# SN32F420 register map
Vendor: SONiX Technology Co., Ltd.; Series: SN32F420; File version: 1.00
CPU: CM0 r0p0, little endian, no MPU, no FPU, 2 interrupt priority bits
Registers are 32-bit, read-write, reset 0x0 unless marked. A register's access mark holds for its fields unless they carry their own. Offsets are from the block's base; [hi:lo] are bit positions.

## SN_DAC — DAC
Base 0x40064000
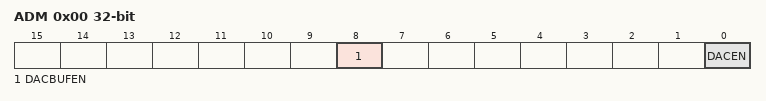
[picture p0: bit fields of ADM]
0x00 ADM — Offset:0x00 DAC Management register
  [8] DACBUFEN — DAC0 Output buffer enable bit
    0=Disable DAO; 1=Enable DAO
  [0] DACEN — DAC0 enable bit
    0=Disable DAC; 1=Enable DAC
0x04 VIREF — Offset:0x04 DAC Internal Reference Voltage Source register
  [0] VIREF — DAC internal reference voltage (VIREF) source
    0=1.2V (DAC internal reference voltage (VIREF) source is 1.2V); 1=4.8V (DAC internal reference voltage (VIREF) source is 4.8V)
0x10 DATACTRL — Offset:0x10 DAC Data Control register
  [7:0] DATA — 8-bit DAC setup data bits.

## SN_ACC — Atan, Div and Sqrt Function
Base 0x40076000
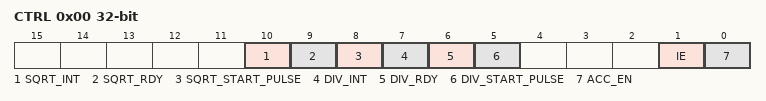
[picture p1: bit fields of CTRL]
0x00 CTRL — Offset:0x00 ACC Hardware Calculation Accelerator Control register
  [10] SQRT_INT — Square root interrupt signal
    0=None (No SQRT interrupt); 1=Meet (SQRT interrupt is triggered)
  [9] SQRT_RDY ro — Square root ready status
    0=Busy (SQRT is operating); 1=Idle (SQRT is not operating)
  [8] SQRT_START_PULSE — Square root operation trigger bit
    0=None (No action); 1=Trigger 1 pulse to start SRQT operating
  [7] DIV_INT — Division interrupt signal
    0=None (No DIV interrupt); 1=Meet (DIV interrupt is triggered)
  [6] DIV_RDY ro — Division ready status
    0=Busy (DIV is operating); 1=Idle (DIV is not operating)
  [5] DIV_START_PULSE — Division operation trigger bit
    0=None (No action); 1=Trigger 1 pulse to start DIV operating
  [1] IE — Hardware calculation accelerator interrupt enable bit
    0=Disable ACC interrupt; 1=Enable ACC interrupt
  [0] ACC_EN — Hardware calculation accelerator enable bit
    0=Disable the hardware accelerator; 1=Enable the hardware accelerator
0x0C DIV_DVD — Offset:0x0C ACC Dividend Input for Division register
  [31:0] DIV_DVD — Dividend input for division in signed 32-bit format
0x10 DIV_DVS — Offset:0x10 ACC Divisor Input for Division register
  [15:0] DIV_DVS — Divisor input for division in signed 16-bit format
0x14 DIV_QUO — Offset:0x14 ACC Quotient Output of Division register
  [31:0] DIV_QUO — Quotient output of division in signed 32-bit format
0x18 DIV_REM — Offset:0x18 ACC Reminder Output of Division register
  [15:0] DIV_REM — Reminder output of division in signed 16-bit format
0x1C SQRT_IN — Offset:0x1C ACC Square Root Input register
  [31:0] SQRT_IN — Square root input value in unsigned 32-bit format
0x20 SQRT_OUT — Offset:0x20 ACC Square Root Output register
  [15:0] SQRT_OUT — Square root output value in unsigned 16-bit format

## SN_HALL — Hall Sensor Interface Function
Base 0x40078000
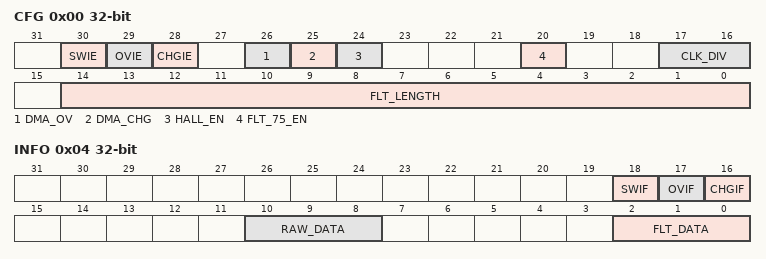
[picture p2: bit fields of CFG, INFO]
0x00 CFG — Offset:0x00 HALL Configuration register
  [30] SWIE — HALL signal SW trigger interrupt enable
    0=Disable HALL signal SW trigger interrupt; 1=Enable HALL signal SW trigger interrupt
  [29] OVIE — HALL signal overflow interrupt enable
    0=Disable HALL signal overflow interrupt; 1=Enable HALL signal overflow interrupt
  [28] CHGIE — HALL signal change interrupt enable
    0=Disable HALL signal change interrupt; 1=Enable HALL signal change interrupt
  [26] DMA_OV — HALL Counter overflow DMA request active enable
    0=Disable HALL Counter overflow DMA request active; 1=Enable HALL Counter overflow DMA request active
  [25] DMA_CHG — HALL signal change DMA request active enable
    0=Disable HALL signal change DMA request active; 1=Enable HALL signal change DMA request active
  [24] HALL_EN — HALL Module enable bit
    0=Disable HALL Module; 1=Enable HALL Module
  [20] FLT_75_EN — 7-out-of-5 filtering enable bit
    0=Disable 7-out-of-5 filtering; 1=Enable 7-out-of-5 filtering
  [17:16] CLK_DIV — Hall sensor module clock source divider
    0=HCLK/1 (Hall sensor module clock source divider = 1); 1=HCLK/2 (Hall sensor module clock source divider = 2); 2=HCLK/4 (Hall sensor module clock source divider = 4); 3=HCLK/8 (Hall sensor module clock source divider = 8)
  [14:0] FLT_LENGTH — The legth of second stage continuous filter.
0x04 INFO — Offset:0x04 HALL Information register
  [18] SWIF — HALL signal SW interrupt trigger.
    0=None; 1=Met (Write 1 to trigger HALL signal(SW))
  [17] OVIF — HALL signal overflow interrupt flag
    0=No (No interrupt requirement met); 1=Met (Interrupt requirements(Counter match HALL_TH) met)
  [16] CHGIF — HALL signal change interrupt flag
    0=No (No interrupt requirement met); 1=Met (Interrupt requirements(Hall signal change) met)
  [10:8] RAW_DATA ro — HALL sensor signal value before filter
  [2:0] FLT_DATA ro — HALL sensor signal value after filter
0x08 WIDTH ro — Offset:0x08 HALL Counter Width register
  [23:0] CAP_INT — The capture width value of the HALL sensor signal Counter
0x0C TH — Offset:0x0C HALL Counter Threshold register
  [23:0] TH — The threshold value of the HALL sensor signal Counter
0x10 CNT — Offset:0x10 HALL Counter register
  [23:0] CNT — The current value of the HALL sensor signal Counter
